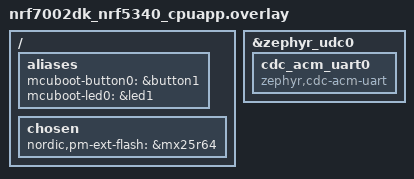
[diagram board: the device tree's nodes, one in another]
/*
 * Copyright (c) 2023 Nordic Semiconductor ASA
 *
 * SPDX-License-Identifier: LicenseRef-Nordic-5-Clause
 */

/* Configure button and LED for Serial Recovery */
/ {
  aliases {
		mcuboot-button0 = &button1;
		mcuboot-led0 = &led1;
  };
};

/ {
	/* Configure the partition manager to use the mx25r64 external flash memory. */
	chosen {
		nordic,pm-ext-flash = &mx25r64;
	};
};

&zephyr_udc0 {
	cdc_acm_uart0: cdc_acm_uart0 {
		compatible = "zephyr,cdc-acm-uart";
	};
};
